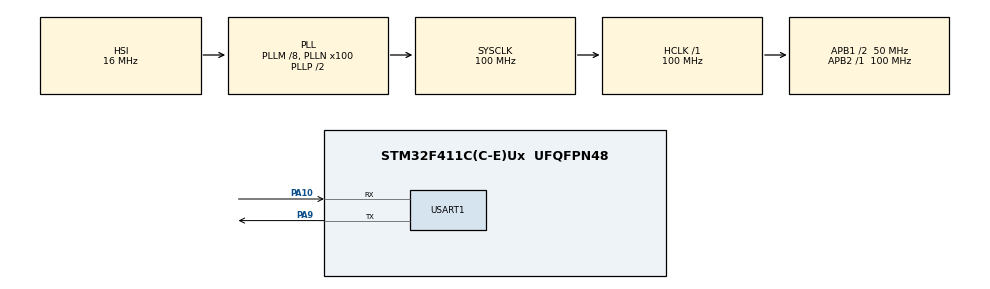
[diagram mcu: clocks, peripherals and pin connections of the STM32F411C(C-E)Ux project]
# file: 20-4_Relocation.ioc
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FREERTOS.Tasks01=defaultTask,24,128,StartDefaultTask,Default,NULL,Dynamic,NULL,NULL
Mcu.Family=STM32F4
Mcu.Name=STM32F411C(C-E)Ux
Mcu.Package=UFQFPN48
NVIC.PriorityGroup=NVIC_PRIORITYGROUP_4
NVIC.TIM1_UP_TIM10_IRQn=true\:15\:0\:false\:false\:true\:false\:false\:true\:true
NVIC.TimeBase=TIM1_UP_TIM10_IRQn
NVIC.TimeBaseIP=TIM1
NVIC.USART1_IRQn=true\:5\:0\:false\:false\:true\:true\:true\:true\:true
PA10.Mode=Asynchronous
PA10.Signal=USART1_RX
PA13.Mode=Serial_Wire
PA13.Signal=SYS_JTMS-SWDIO
PA14.Mode=Serial_Wire
PA14.Signal=SYS_JTCK-SWCLK
PA9.Mode=Asynchronous
PA9.Signal=USART1_TX
PC14-OSC32_IN.Mode=LSE-External-Oscillator
PC14-OSC32_IN.Signal=RCC_OSC32_IN
PC15-OSC32_OUT.Mode=LSE-External-Oscillator
PC15-OSC32_OUT.Signal=RCC_OSC32_OUT
PH0\ -\ OSC_IN.Mode=HSE-External-Oscillator
PH0\ -\ OSC_IN.Signal=RCC_OSC_IN
PH1\ -\ OSC_OUT.Mode=HSE-External-Oscillator
PH1\ -\ OSC_OUT.Signal=RCC_OSC_OUT
ProjectManager.HeapSize=0x200
ProjectManager.StackSize=0x400
ProjectManager.TargetToolchain=MDK-ARM V5.32
RCC.48MHZClocksFreq_Value=50000000
RCC.AHBFreq_Value=100000000
RCC.APB1CLKDivider=RCC_HCLK_DIV2
RCC.APB1Freq_Value=50000000
RCC.APB1TimFreq_Value=100000000
RCC.APB2Freq_Value=100000000
RCC.APB2TimFreq_Value=100000000
RCC.CortexFreq_Value=100000000
RCC.HCLKFreq_Value=100000000
RCC.HSE_VALUE=25000000
RCC.HSI_VALUE=16000000
RCC.PLLM=8
RCC.PLLN=100
RCC.SYSCLKFreq_VALUE=100000000
RCC.SYSCLKSource=RCC_SYSCLKSOURCE_PLLCLK
RCC.VCOOutputFreq_Value=200000000
USART1.VirtualMode=VM_ASYNC
VP_FREERTOS_VS_CMSIS_V2.Mode=CMSIS_V2
VP_SYS_VS_tim1.Mode=TIM1
board=custom

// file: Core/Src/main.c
/* USER CODE BEGIN Header */
/**
  ******************************************************************************
  * @file           : main.c
  * @brief          : Main program body
  ******************************************************************************
  * @attention
  *
  * Copyright (c) 2026 STMicroelectronics.
  * All rights reserved.
  *
  * This software is licensed under terms that can be found in the LICENSE file
  * in the root directory of this software component.
  * If no LICENSE file comes with this software, it is provided AS-IS.
  *
  ******************************************************************************
  */
/* USER CODE END Header */
#include "main.h"
#include "cmsis_os.h"
#include "usart.h"
#include "gpio.h"

/* USER CODE BEGIN Includes */
#include <stdio.h>
/* USER CODE END Includes */

/* USER CODE BEGIN PV */

extern uint32_t Load$$RW_IRAM1$$RW$$Base ;       // int
extern uint32_t Load$$RW_IRAM1$$RW$$Limit ;
extern uint32_t Load$$RW_IRAM1$$ZI$$Base ;
extern uint32_t Load$$RW_IRAM1$$ZI$$Limit ;
extern uint32_t Image$$RW_IRAM1$$RW$$Base ;
extern uint32_t Image$$RW_IRAM1$$RW$$Limit ;
extern uint32_t Image$$RW_IRAM1$$ZI$$Base ;
extern uint32_t Image$$RW_IRAM1$$ZI$$Limit ;

/* USER CODE END PV */

void SystemClock_Config(void);
void MX_FREERTOS_Init(void);

/* USER CODE BEGIN 0 */

/*------------------------------------- Relocation ---------------------------*/

/**
 * @brief  内存搬运函数
 *
 * @param [in]  desc_addr
 * @param [in]  source_addr
 * @param [in]  size
 * @return
 *
 * @details
 * @note
 * @warning
 */
uint8_t    MemoryCopy(uint32_t *desc_addr, uint32_t *source_addr, uint32_t size)
{
    if( NULL == desc_addr || NULL == source_addr )
    {
        return 0 ;
    }
    //uint32_t * end = source_addr + size ;
    while (size--)
    {
        *desc_addr++ = *source_addr++ ;
    }
}

/**
 * @brief   ZI  段初始化为 0
 *
 * @param [in]  start_addr
 * @param [in]  end_addr
 * @return
 *
 * @details
 * @note
 * @warning
 */
uint8_t ZI_SectionInit(uint32_t * start_addr, uint32_t * end_addr)
{
    if( NULL == start_addr || NULL == end_addr )
    {
        return 0 ;
    }
    uint32_t * cur_addr = start_addr ;
    while (cur_addr < end_addr)
    {
        *cur_addr++ = 0x00;
    }

}

/*------------------------------------- Relocation ---------------------------*/

/* USER CODE END 0 */

int main(void)
{
  /* USER CODE BEGIN 1 */
/*------------------------------------- Relocation ---------------------------*/
    // MemoryCopy( (uint32_t * )&Image$$RW_IRAM1$$RW$$Base, (uint32_t * )&Load$$RW_IRAM1$$RW$$Base,
    //             (uint32_t)&Load$$RW_IRAM1$$RW$$Limit - (uint32_t)&Load$$RW_IRAM1$$RW$$Base) ;   // 这里为什么不能直接用32位的int来做计算，而是要通过地址转换再进行计算
		MemoryCopy(
				(uint32_t *)&Image$$RW_IRAM1$$RW$$Base,
				(uint32_t *)&Load$$RW_IRAM1$$RW$$Base,
				((uint32_t)&Image$$RW_IRAM1$$RW$$Limit -
								 (uint32_t)&Image$$RW_IRAM1$$RW$$Base));     /* 这里的执行区和加载区的大小是一样的吗？一定要用执行区的大小吗 ？*/

    ZI_SectionInit( (uint32_t * )&Image$$RW_IRAM1$$ZI$$Base, (uint32_t * )&Image$$RW_IRAM1$$ZI$$Limit );
/*------------------------------------- Relocation ---------------------------*/
  /* USER CODE END 1 */

  /* MCU Configuration--------------------------------------------------------*/

  /* Reset of all peripherals, Initializes the Flash interface and the Systick. */
  HAL_Init();

  /* Configure the system clock */
  SystemClock_Config();

  /* Initialize all configured peripherals */
  MX_GPIO_Init();
  MX_USART1_UART_Init();
  /* USER CODE BEGIN 2 */

/*------------------------------------- Relocation ---------------------------*/

    printf("hello world");

    printf(" 0x%x: 0x%x 0x%x 0x%x 0x%x 0x%x 0x%x 0x%x \r\n",
            &Load$$RW_IRAM1$$RW$$Base, &Load$$RW_IRAM1$$RW$$Limit,
            &Load$$RW_IRAM1$$ZI$$Base, &Load$$RW_IRAM1$$ZI$$Limit,
            &Image$$RW_IRAM1$$RW$$Base, &Image$$RW_IRAM1$$RW$$Limit,
            &Image$$RW_IRAM1$$ZI$$Base, &Image$$RW_IRAM1$$ZI$$Limit);

/*------------------------------------- Relocation ---------------------------*/

  /* USER CODE END 2 */

  /* Init scheduler */
  osKernelInitialize();  /* Call init function for freertos objects (in freertos.c) */
  MX_FREERTOS_Init();

  /* Start scheduler */
  osKernelStart();
  /* We should never get here as control is now taken by the scheduler */
  /* Infinite loop */
  while (1)
  {

  }
}

void SystemClock_Config(void)
{
  RCC_OscInitTypeDef RCC_OscInitStruct = {0};
  RCC_ClkInitTypeDef RCC_ClkInitStruct = {0};

  /** Configure the main internal regulator output voltage
  */
  __HAL_RCC_PWR_CLK_ENABLE();
  __HAL_PWR_VOLTAGESCALING_CONFIG(PWR_REGULATOR_VOLTAGE_SCALE1);

  /** Initializes the RCC Oscillators according to the specified parameters
  * in the RCC_OscInitTypeDef structure.
  */
  RCC_OscInitStruct.OscillatorType = RCC_OSCILLATORTYPE_HSI;
  RCC_OscInitStruct.HSIState = RCC_HSI_ON;
  RCC_OscInitStruct.HSICalibrationValue = RCC_HSICALIBRATION_DEFAULT;
  RCC_OscInitStruct.PLL.PLLState = RCC_PLL_ON;
  RCC_OscInitStruct.PLL.PLLSource = RCC_PLLSOURCE_HSI;
  RCC_OscInitStruct.PLL.PLLM = 8;
  RCC_OscInitStruct.PLL.PLLN = 100;
  RCC_OscInitStruct.PLL.PLLP = RCC_PLLP_DIV2;
  RCC_OscInitStruct.PLL.PLLQ = 4;
  if (HAL_RCC_OscConfig(&RCC_OscInitStruct) != HAL_OK)
  {
    Error_Handler();
  }

  /** Initializes the CPU, AHB and APB buses clocks
  */
  RCC_ClkInitStruct.ClockType = RCC_CLOCKTYPE_HCLK|RCC_CLOCKTYPE_SYSCLK
                              |RCC_CLOCKTYPE_PCLK1|RCC_CLOCKTYPE_PCLK2;
  RCC_ClkInitStruct.SYSCLKSource = RCC_SYSCLKSOURCE_PLLCLK;
  RCC_ClkInitStruct.AHBCLKDivider = RCC_SYSCLK_DIV1;
  RCC_ClkInitStruct.APB1CLKDivider = RCC_HCLK_DIV2;
  RCC_ClkInitStruct.APB2CLKDivider = RCC_HCLK_DIV1;

  if (HAL_RCC_ClockConfig(&RCC_ClkInitStruct, FLASH_LATENCY_3) != HAL_OK)
  {
    Error_Handler();
  }
}

void HAL_TIM_PeriodElapsedCallback(TIM_HandleTypeDef *htim)
{
  if (htim->Instance == TIM1) {
    HAL_IncTick();
  }
}

void Error_Handler(void)
{
  __disable_irq();
  while (1)
  {
  }
}
